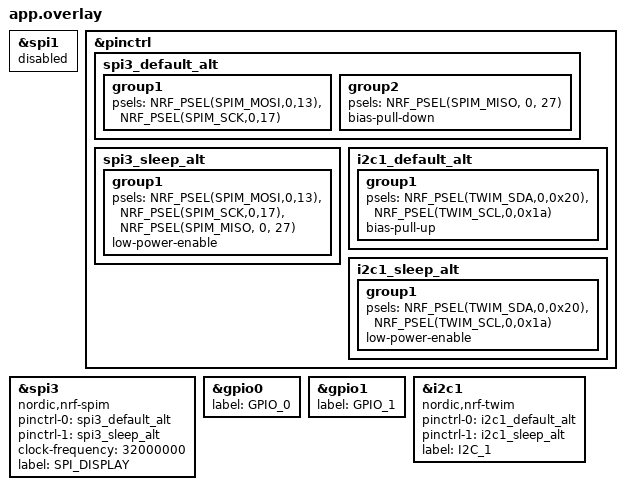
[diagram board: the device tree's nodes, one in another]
/*
 *
 * SPDX-License-Identifier: Apache-2.0
 */


&spi1 {
	status = "disabled";
};

&pinctrl {
    /* IMPORTANT!  There should not be a space before the : in the next line (and similar below) */
    spi3_default_alt: spi3_default_alt {
        group1 {
            psels = <NRF_PSEL(SPIM_MOSI,0,13)>,
                    <NRF_PSEL(SPIM_SCK,0,17)>;
        };
        group2 {
        psels = <NRF_PSEL(SPIM_MISO, 0, 27)>;
        bias-pull-down;
        };
        
    };
    spi3_sleep_alt: spi3_sleep_alt {
        group1 {
            psels = <NRF_PSEL(SPIM_MOSI,0,13)>,
                    <NRF_PSEL(SPIM_SCK,0,17)>,
                    <NRF_PSEL(SPIM_MISO, 0, 27)>;
            low-power-enable;
        };
    };

    i2c1_default_alt: i2c1_default_alt {
        group1 {
            psels = <NRF_PSEL(TWIM_SDA,0,0x20)>,
                    <NRF_PSEL(TWIM_SCL,0,0x1a)>;
            bias-pull-up;
        };
    };
    i2c1_sleep_alt: i2c1_sleep_alt {
        group1 {
            psels = <NRF_PSEL(TWIM_SDA,0,0x20)>,
                    <NRF_PSEL(TWIM_SCL,0,0x1a)>;
            low-power-enable;
        };
    };

    
    
};
&spi3 {
    compatible = "nordic,nrf-spim";
    status = "okay";
    pinctrl-0 = <&spi3_default_alt>;
    pinctrl-1 = <&spi3_sleep_alt>;
    pinctrl-names = "default", "sleep";
    clock-frequency = <32000000>;
    label = "SPI_DISPLAY";
};
&gpio0 {

    status = "okay";
    label = "GPIO_0";
};
&gpio1 {

    status = "okay";
    label = "GPIO_1";
};
&i2c1 {
    compatible = "nordic,nrf-twim";
    status = "okay";
    pinctrl-0 = <&i2c1_default_alt>;
    pinctrl-1 = <&i2c1_sleep_alt>;
    pinctrl-names = "default", "sleep";
    label = "I2C_1";

};
